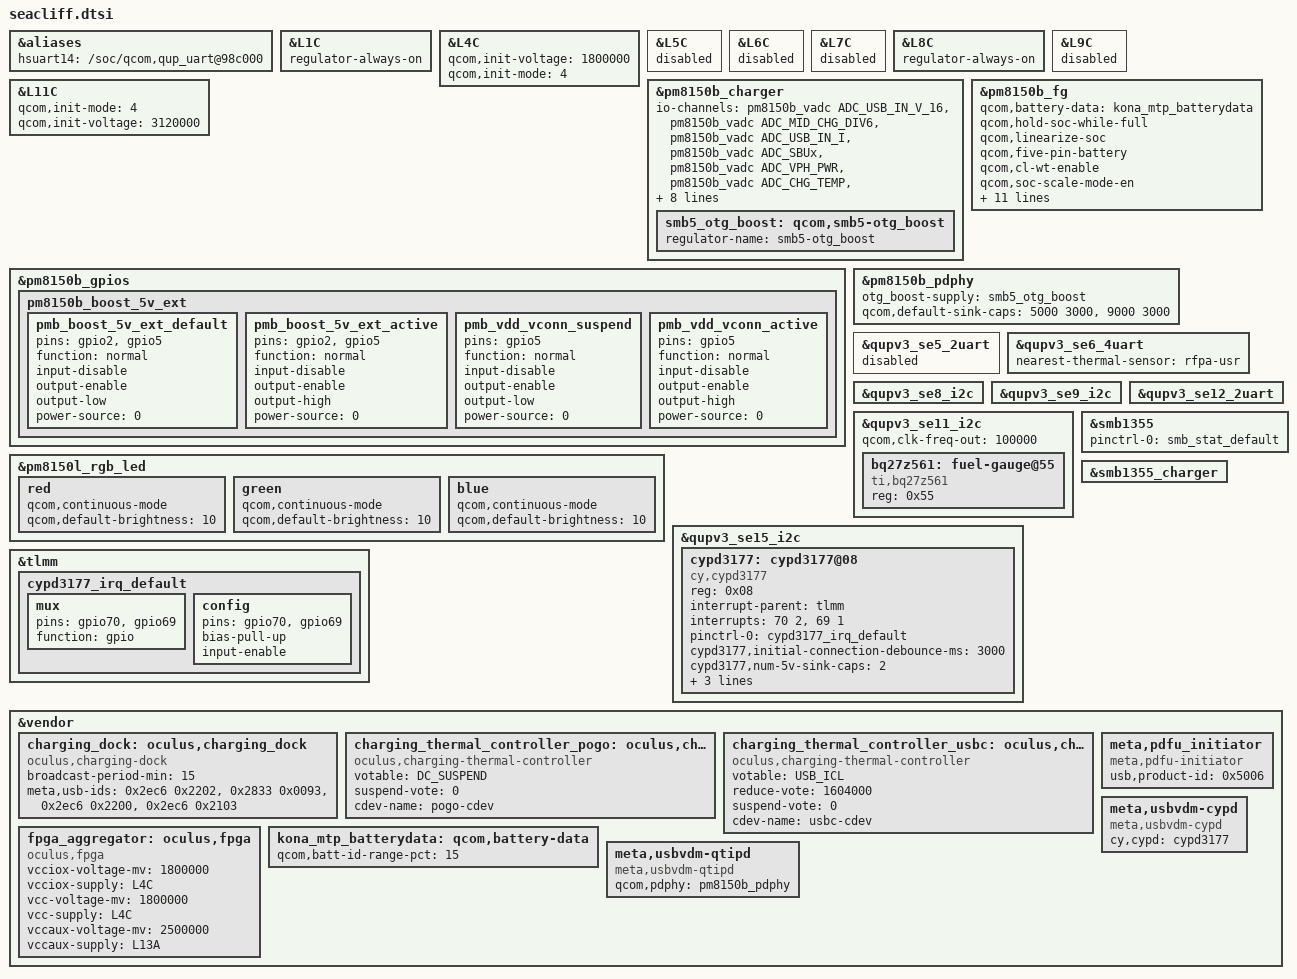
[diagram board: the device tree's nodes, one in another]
#include <dt-bindings/interrupt-controller/arm-gic.h>

#include "../vendor/qcom/kona-pmic-overlay.dtsi"
#include "../vendor/qcom/kona-sde-display.dtsi"

#include "kona-oculus.dtsi"
#include "seacliff-adc.dtsi"
#include "seacliff-audio.dtsi"
#include "seacliff-bcmdhd.dtsi"
#include "seacliff-camera.dtsi"
#include "seacliff-fan.dtsi"
#include "seacliff-pac1934.dtsi"
#include "seacliff-panel.dtsi"
#include "seacliff-syncboss.dtsi"
#include "seacliff-thermal.dtsi"
#include "seacliff-ufs.dtsi"

&aliases {
	hsuart14 = "/soc/qcom,qup_uart@98c000";
};

&L1C {
	/* IPD 1.8 */
	regulator-always-on;
};

&L4C {
	/* FPGA aggregator 1.8 */
	status = "ok";
	qcom,init-voltage = <1800000>;
	qcom,init-mode = <4>; /* RPMH_REGULATOR_MODE_HPM */
};

&L5C {
	status = "disabled";
};

&L6C {
	status = "disabled";
};

&L7C {
	status = "disabled";
};

&L8C {
	/* nRF, IMU, Mag 1.8 */
	regulator-always-on;
};

&L9C {
	status = "disabled";
};

&L11C {
	qcom,init-mode = <4>; /* RPMH_REGULATOR_MODE_HPM */
	qcom,init-voltage = <3120000>;
};

&pm8150b_charger {
	io-channels = <&pm8150b_vadc ADC_USB_IN_V_16>,
		      <&pm8150b_vadc ADC_MID_CHG_DIV6>,
		      <&pm8150b_vadc ADC_USB_IN_I>,
		      <&pm8150b_vadc ADC_SBUx>,
		      <&pm8150b_vadc ADC_VPH_PWR>,
		      <&pm8150b_vadc ADC_CHG_TEMP>,
		      <&pm8150b_vadc ADC_AMUX_THM3_PU2>,
		      <&pm8150b_vadc ADC_GPIO4>;
	io-channel-names = "usb_in_voltage",
			   "mid_voltage",
			   "usb_in_current",
			   "sbux_res",
			   "vph_voltage",
			   "chg_temp",
			   "rblt_res",
			   "psns_res";
	dcin-icl-uv = <40000>;
	wls-psy-name = "cypd3177";

	pinctrl-names = "default", "boost_5v_active",
			"vdd_vconn_suspend", "vdd_vconn_active";
	pinctrl-0 = <&pmb_boost_5v_ext_default>;
	pinctrl-1 = <&pmb_boost_5v_ext_active>;
	pinctrl-2 = <&pmb_vdd_vconn_suspend>;
	pinctrl-3 = <&pmb_vdd_vconn_active>;

	smb5_otg_boost: qcom,smb5-otg_boost {
		regulator-name = "smb5-otg_boost";
	};
};

&pm8150b_fg {
	status = "ok";
	qcom,battery-data = <&kona_mtp_batterydata>;
	qcom,hold-soc-while-full;
	qcom,linearize-soc;
	qcom,five-pin-battery;
	qcom,cl-wt-enable;
	qcom,soc-scale-mode-en;
	qcom,soc-scale-vbatt-mv = <3500>;
	/* ESR fast calibration */
	qcom,fg-esr-timer-chg-fast = <0 7>;
	qcom,fg-esr-timer-dischg-fast = <0 7>;
	qcom,fg-esr-timer-chg-slow = <0 96>;
	qcom,fg-esr-timer-dischg-slow = <0 96>;
	qcom,fg-esr-cal-soc-thresh = <26 230>;
	qcom,fg-esr-cal-temp-thresh = <10 40>;

	qcom,fg-sys-term-current = <(-350)>; // charger termination < fg termination see section 1.6.3 (80-PD996-14. Rev B)
	qcom,fg-cutoff-current = <268>; // C/20 minimum discharge current at system cutoff for SOC estimation
	qcom,fg-cutoff-voltage = <3300>;
	qcom,fg-empty-voltage = <3100>; // see section 4.4.6 (80-PF777-74. Rev C)
};

&pm8150b_gpios {
	pm8150b_boost_5v_ext {
		pmb_boost_5v_ext_default: pmb_boost_5v_ext_default {
			pins = "gpio2", "gpio5";
			function = "normal";
			input-disable;
			output-enable;
			output-low;
			power-source = <0>;
		};
		pmb_boost_5v_ext_active: pmb_boost_5v_ext_active {
			pins = "gpio2", "gpio5";
			function = "normal";
			input-disable;
			output-enable;
			output-high;
			power-source = <0>;
		};

		pmb_vdd_vconn_suspend: pmb_vdd_vconn_suspend {
			pins = "gpio5";
			function = "normal";
			input-disable;
			output-enable;
			output-low;
			power-source = <0>;
		};

		pmb_vdd_vconn_active: pmb_vdd_vconn_active {
			pins = "gpio5";
			function = "normal";
			input-disable;
			output-enable;
			output-high;
			power-source = <0>;
		};
	};
};

&pm8150b_pdphy {
	otg_boost-supply = <&smb5_otg_boost>;
	qcom,default-sink-caps = <5000 3000>, /* 5V @ 3A */
		<9000 3000>; /* 9V @ 3A */
};

&pm8150l_rgb_led {
	red {
		qcom,continuous-mode;
		qcom,default-brightness = <10>;
	};
	green {
		qcom,continuous-mode;
		qcom,default-brightness = <10>;
	};
	blue {
		qcom,continuous-mode;
		qcom,default-brightness = <10>;
	};
};

&qupv3_se5_2uart {
	status = "disabled";
};

&qupv3_se6_4uart {
	status = "ok";
	nearest-thermal-sensor = "rfpa-usr";
};

&qupv3_se8_i2c {
	status = "ok";
};

&qupv3_se9_i2c {
	status = "ok";
};

&qupv3_se11_i2c {
	status = "ok";
	qcom,clk-freq-out = <100000>;

	bq27z561: fuel-gauge@55 {
		compatible = "ti,bq27z561";
		reg = <0x55>;
		status = "okay";
	};
};

&qupv3_se12_2uart {
	status = "ok";
};

&qupv3_se15_i2c {
	#include "../vendor/qcom/smb1355.dtsi"

	cypd3177: cypd3177@08 {
		compatible = "cy,cypd3177";
		reg = <0x08>;
		status = "ok";
		interrupt-parent = <&tlmm>;
		interrupts = <70 2>, <69 1>;
		interrupt-names = "cypd3177_hpi_irq", "cypd3177_fault_irq";
		pinctrl-names = "default";
		pinctrl-0 = <&cypd3177_irq_default>;
		cypd3177,initial-connection-debounce-ms = <3000>;

		cypd3177,num-5v-sink-caps = <2>;
		cypd3177,custom-sink-caps = <5000 2200>, /* 5V @ 2.2A */
		<5000 2600>, /* 5V @ 2.6A */
		<9000 1600>, /* 9V @ 1.6A */
		<9000 1900>, /* 9V @ 1.9A */
		<9000 2100>, /* 9V @ 2.1A */
		<9000 2400>, /* 9V @ 2.4A */
		<9000 2900>; /* 9V @ 2.9A */
	};
};

&smb1355 {
	pinctrl-names = "default";
	pinctrl-0 = <&smb_stat_default>;
	status = "ok";
};

&smb1355_charger {
	status = "ok";
};

&tlmm {
	cypd3177_irq_default: cypd3177_irq_default {
		mux {
			pins = "gpio70", "gpio69";
			function = "gpio";
		};
		config {
			pins = "gpio70", "gpio69";
			bias-pull-up;
			input-enable;
		};
	};
};

&vendor {
	charging_dock: oculus,charging_dock {
		compatible = "oculus,charging-dock";
		broadcast-period-min = <15>;
		meta,usb-ids =
			/bits/ 16 <0x2ec6 0x2202>,		/* Buru */
			/bits/ 16 <0x2833 0x0093>,		/* Skellig */
			/bits/ 16 <0x2ec6 0x2200>,		/* UPA 18W */
			/bits/ 16 <0x2ec6 0x2103>;		/* UPA 45W */
	};

	charging_thermal_controller_pogo: oculus,charging_thermal_controller_pogo {
		status = "ok";
		compatible = "oculus,charging-thermal-controller";
		votable = "DC_SUSPEND";
		suspend-vote = <0>;
		cdev-name = "pogo-cdev";
		#cooling-cells = <2>;
	};

	charging_thermal_controller_usbc: oculus,charging_thermal_controller_usbc {
		status = "ok";
		compatible = "oculus,charging-thermal-controller";
		votable = "USB_ICL";
		reduce-vote = <1604000>;
		suspend-vote = <0>;
		cdev-name = "usbc-cdev";
		#cooling-cells = <2>;
	};

	fpga_aggregator: oculus,fpga {
		status = "ok";
		compatible = "oculus,fpga";
		vcciox-voltage-mv = <1800000>;
		vcciox-supply = <&L4C>;
		vcc-voltage-mv = <1800000>;
		vcc-supply = <&L4C>;
		vccaux-voltage-mv = <2500000>;
		vccaux-supply = <&L13A>;
	};

	kona_mtp_batterydata: qcom,battery-data {
		qcom,batt-id-range-pct = <15>;
		#include "4081226_Goertek_Hollywood_15k_3636mAh_Aug26th2019.dtsi"
		#include "4203348_Goertek_Hollywood_100k_3636mAh_Oct21st2019.dtsi"
		#include "4759214_Facebook_Seacliff_5348mAH_averaged_MasterSlave_Feb17th2021_PM8150B_GUI10014.dtsi"
		#include "5133886_Facebook_Seacliff_5348mAH_averaged_MasterSlave_Apr23rd2021_PM8150B_GUI10014.dtsi"
	};

	meta,pdfu_initiator {
		compatible = "meta,pdfu-initiator";
		usb,product-id = /bits/ 16 <0x5006>;
	};

	meta,usbvdm-qtipd {
		compatible = "meta,usbvdm-qtipd";
		qcom,pdphy = <&pm8150b_pdphy>;
	};

	meta,usbvdm-cypd {
		compatible = "meta,usbvdm-cypd";
		cy,cypd = <&cypd3177>;
	};
};
